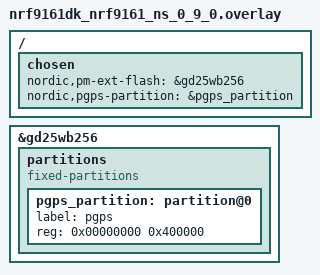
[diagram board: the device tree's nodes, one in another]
/*
 * Copyright (c) 2023 Nordic Semiconductor ASA
 *
 * SPDX-License-Identifier: LicenseRef-Nordic-5-Clause
 */

/ {
	/* Configure partition manager to use gd25wb256 as the external flash */
	chosen {
		nordic,pm-ext-flash = &gd25wb256;
		nordic,pgps-partition = &pgps_partition;
	};
};

#include <samples/cellular/nrf91_bootloader_partitions.dtsi>

&gd25wb256 {
	status = "okay";

	partitions {
		compatible = "fixed-partitions";
		#address-cells = <1>;
		#size-cells = <1>;

		pgps_partition: partition@0 {
			label = "pgps";
			reg = <0x00000000 0x400000>;
		};
	};
};

#include <samples/cellular/nrf91_sram_partitions.dtsi>
